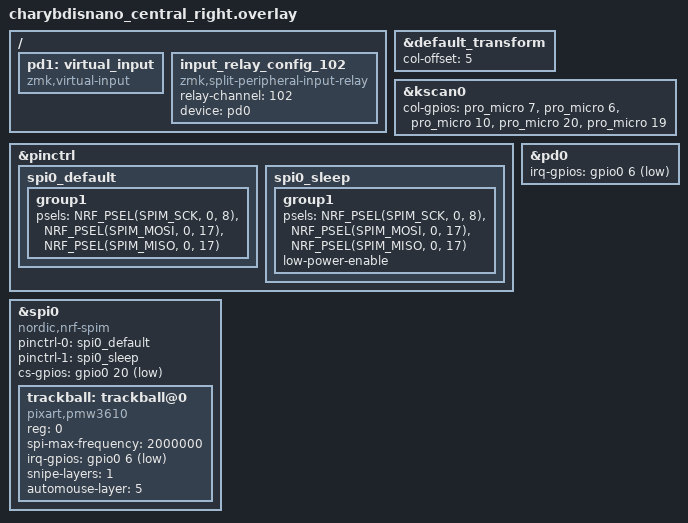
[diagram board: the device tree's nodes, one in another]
/*
 * Copyright (c) 2020 ZMK Contributors
 *
 * SPDX-License-Identifier: MIT
 */
 
#include "charybdisnano.dtsi"

&default_transform {
	col-offset = <5>;
};

&kscan0 {
	col-gpios
		= <&pro_micro 7 GPIO_ACTIVE_HIGH>
		, <&pro_micro 6 GPIO_ACTIVE_HIGH>
		, <&pro_micro 10 GPIO_ACTIVE_HIGH>
		, <&pro_micro 20 GPIO_ACTIVE_HIGH> 
		, <&pro_micro 19 GPIO_ACTIVE_HIGH>
		;
};

// trackball bus
&pinctrl {
    spi0_default: spi0_default {
        group1 {
            psels = <NRF_PSEL(SPIM_SCK, 0, 8)>,
                <NRF_PSEL(SPIM_MOSI, 0, 17)>,
                <NRF_PSEL(SPIM_MISO, 0, 17)>;
        };
    };

    spi0_sleep: spi0_sleep {
        group1 {
            psels = <NRF_PSEL(SPIM_SCK, 0, 8)>,
                <NRF_PSEL(SPIM_MOSI, 0, 17)>,
                <NRF_PSEL(SPIM_MISO, 0, 17)>;
            low-power-enable;
        };
    };
};

&spi0 {
    status = "okay";
    compatible = "nordic,nrf-spim";
    pinctrl-0 = <&spi0_default>;
    pinctrl-1 = <&spi0_sleep>;
    pinctrl-names = "default", "sleep";
    cs-gpios = <&gpio0 20 GPIO_ACTIVE_LOW>;

    trackball: trackball@0 {
        status = "okay";
        compatible = "pixart,pmw3610";
        reg = <0>;
        spi-max-frequency = <2000000>;
        irq-gpios = <&gpio0 6 (GPIO_ACTIVE_LOW | GPIO_PULL_UP)>;

        /*   optional features   */
        snipe-layers = <1>;
        //scroll-layers = <2>;
        automouse-layer = <5>;
    };
};

/* enable &pd0 on central. typical input device for zephyr input subsystem. */
/* NOTE 1: use the same device alias (&pd0) on central and peripheral(s) is alright. */

/* this is an alias of your actual wired input device sensor in your central shield. */
/* e.g. SPI optical sensor for trackball */
&pd0 {
	status = "okay";
    irq-gpios = <&gpio0 6 (GPIO_ACTIVE_LOW | GPIO_PULL_UP)>;
	/* the rest of sensor config should be config here, e.g. gpios */
};

/ {
	/* define virtual input, will be resurrected for emitting input event */
	/* NOTE: set `device = <&pd1>` in `zmk,input-listener` */
	pd1: virtual_input {
		compatible = "zmk,virtual-input";
	};

	/* for central side, define (relay-channel)-to-(virtual-input) mapping */
	input_relay_config_102 {
		compatible = "zmk,split-peripheral-input-relay";
		
		/* channel id, used to filter incoming input event from split peripheral */
		/* NOTE: should matching relay-channel on peripheral overlay */
		relay-channel = <102>;

		/* virtual input device on central, which used to emit input event as an agent device */
		device = <&pd0>;
	};
};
